# PIC32MM0032GPL036 device description
Architecture: MIPS; Family: PIC32MM1324; Series: PIC32MM
Registers are 32-bit, read-write, no defined reset value unless marked. A register's access mark holds for its fields unless they carry their own. Offsets are from the block's base; [hi:lo] are bit positions; {n}, {i} and the like mark numbered series.

## GPIO
Instances: GPIO 0x1f802300 in periph0
0x180 RPCON
  [11] IOLOCK
0x1A0 RPINR1
  [4:0] INT4R
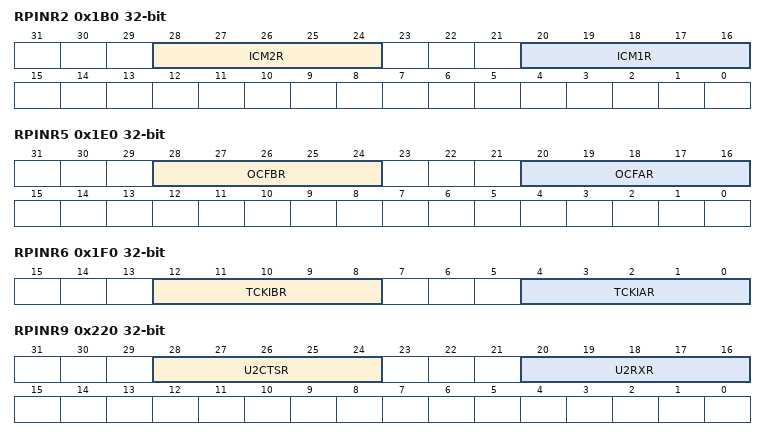
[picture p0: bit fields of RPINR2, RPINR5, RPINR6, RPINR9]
0x1B0 RPINR2
  [28:24] ICM2R, [20:16] ICM1R
0x1C0 RPINR3
  [4:0] ICM3R
0x1E0 RPINR5
  [28:24] OCFBR, [20:16] OCFAR
0x1F0 RPINR6
  [12:8] TCKIBR, [4:0] TCKIAR
0x220 RPINR9
  [28:24] U2CTSR, [20:16] U2RXR
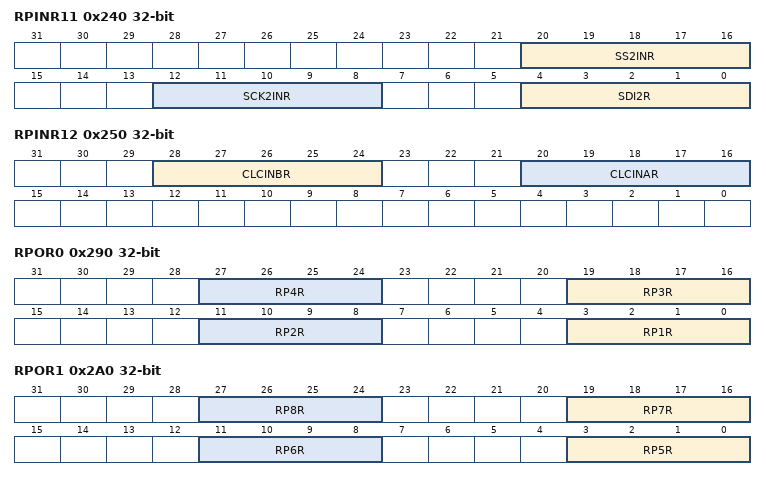
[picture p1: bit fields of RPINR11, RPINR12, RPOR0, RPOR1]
0x240 RPINR11
  [20:16] SS2INR, [12:8] SCK2INR, [4:0] SDI2R
0x250 RPINR12
  [28:24] CLCINBR, [20:16] CLCINAR
0x290 RPOR0
  [8n-5:8n-8] RP{n}R (n=1..4)
0x2A0 RPOR1
  [8n-37:8n-40] RP{n}R (n=5..8)
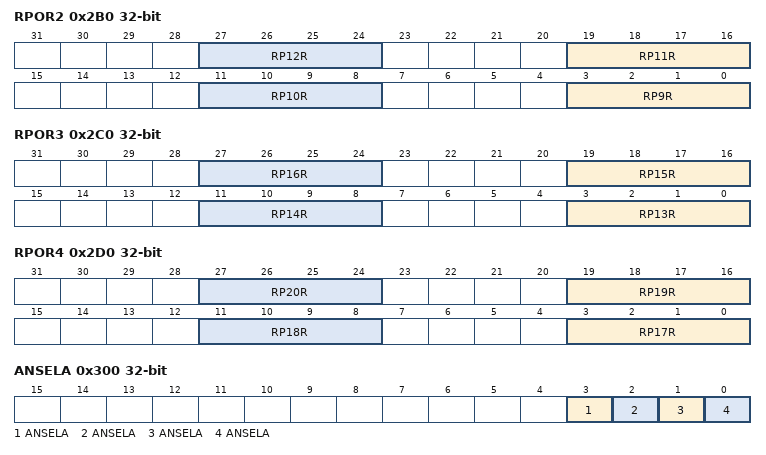
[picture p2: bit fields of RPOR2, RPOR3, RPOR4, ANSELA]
0x2B0 RPOR2
  [8n-69:8n-72] RP{n}R (n=9..12)
0x2C0 RPOR3
  [8n-101:8n-104] RP{n}R (n=13..16)
0x2D0 RPOR4
  [8n-133:8n-136] RP{n}R (n=17..20)
0x300 ANSELA
  [3] ANSELA, [2] ANSELA, [1] ANSELA, [0] ANSELA
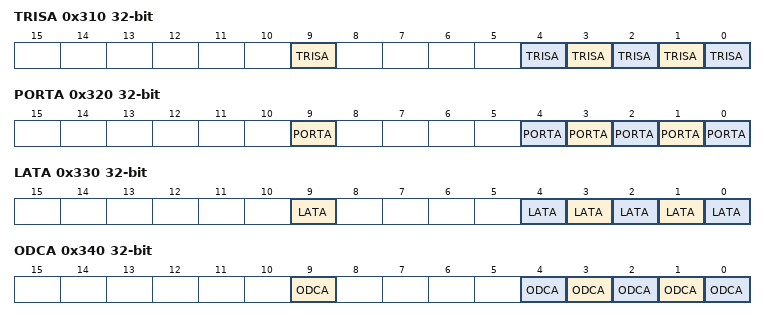
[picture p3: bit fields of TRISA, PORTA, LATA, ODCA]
0x310 TRISA
  [9] TRISA, [4] TRISA, [3] TRISA, [2] TRISA, [1] TRISA, [0] TRISA
0x320 PORTA
  [9] PORTA, [4] PORTA, [3] PORTA, [2] PORTA, [1] PORTA, [0] PORTA
0x330 LATA
  [9] LATA, [4] LATA, [3] LATA, [2] LATA, [1] LATA, [0] LATA
0x340 ODCA
  [9] ODCA, [4] ODCA, [3] ODCA, [2] ODCA, [1] ODCA, [0] ODCA
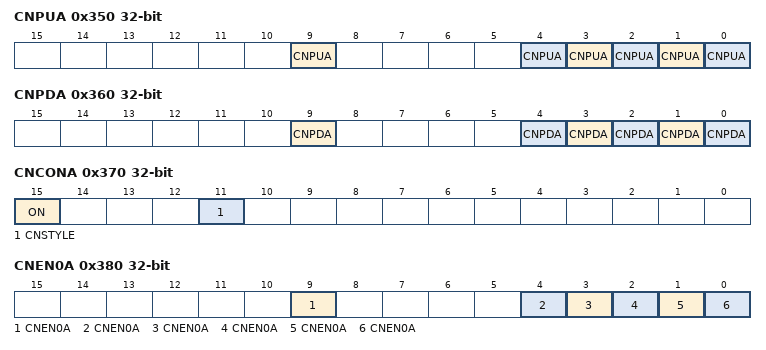
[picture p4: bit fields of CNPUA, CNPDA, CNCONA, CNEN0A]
0x350 CNPUA
  [9] CNPUA, [4] CNPUA, [3] CNPUA, [2] CNPUA, [1] CNPUA, [0] CNPUA
0x360 CNPDA
  [9] CNPDA, [4] CNPDA, [3] CNPDA, [2] CNPDA, [1] CNPDA, [0] CNPDA
0x370 CNCONA
  [15] ON, [11] CNSTYLE
0x380 CNEN0A
  [9] CNEN0A, [4] CNEN0A, [3] CNEN0A, [2] CNEN0A, [1] CNEN0A, [0] CNEN0A
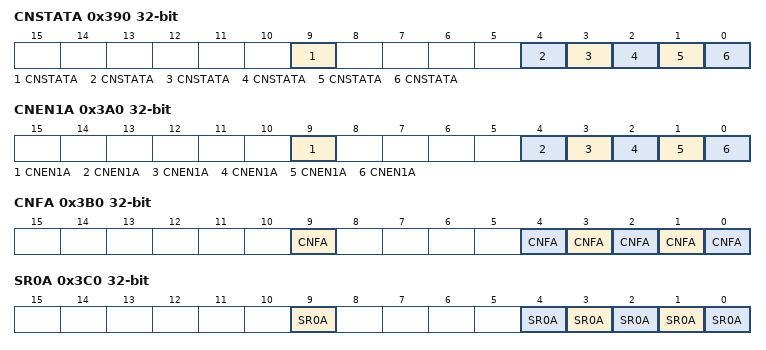
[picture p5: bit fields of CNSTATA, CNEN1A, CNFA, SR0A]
0x390 CNSTATA
  [9] CNSTATA, [4] CNSTATA, [3] CNSTATA, [2] CNSTATA, [1] CNSTATA, [0] CNSTATA
0x3A0 CNEN1A
  [9] CNEN1A, [4] CNEN1A, [3] CNEN1A, [2] CNEN1A, [1] CNEN1A, [0] CNEN1A
0x3B0 CNFA
  [9] CNFA, [4] CNFA, [3] CNFA, [2] CNFA, [1] CNFA, [0] CNFA
0x3C0 SR0A
  [9] SR0A, [4] SR0A, [3] SR0A, [2] SR0A, [1] SR0A, [0] SR0A
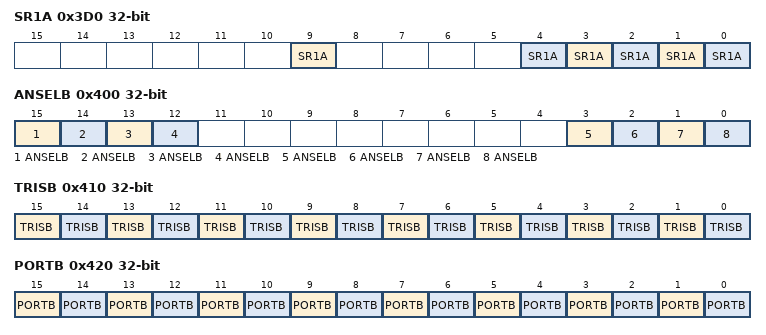
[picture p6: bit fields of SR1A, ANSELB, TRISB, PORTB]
0x3D0 SR1A
  [9] SR1A, [4] SR1A, [3] SR1A, [2] SR1A, [1] SR1A, [0] SR1A
0x400 ANSELB
  [15] ANSELB, [14] ANSELB, [13] ANSELB, [12] ANSELB, [3] ANSELB, [2] ANSELB, [1] ANSELB, [0] ANSELB
0x410 TRISB
  [15] TRISB, [14] TRISB, [13] TRISB, [12] TRISB, [11] TRISB, [10] TRISB, [9] TRISB, [8] TRISB, [7] TRISB, [6] TRISB, [5] TRISB, [4] TRISB, [3] TRISB, [2] TRISB, [1] TRISB, [0] TRISB
0x420 PORTB
  [15] PORTB, [14] PORTB, [13] PORTB, [12] PORTB, [11] PORTB, [10] PORTB, [9] PORTB, [8] PORTB, [7] PORTB, [6] PORTB, [5] PORTB, [4] PORTB, [3] PORTB, [2] PORTB, [1] PORTB, [0] PORTB
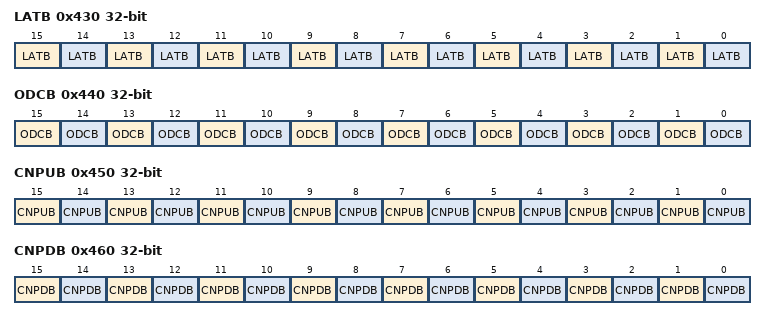
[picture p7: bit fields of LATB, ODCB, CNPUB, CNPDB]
0x430 LATB
  [15] LATB, [14] LATB, [13] LATB, [12] LATB, [11] LATB, [10] LATB, [9] LATB, [8] LATB, [7] LATB, [6] LATB, [5] LATB, [4] LATB, [3] LATB, [2] LATB, [1] LATB, [0] LATB
0x440 ODCB
  [15] ODCB, [14] ODCB, [13] ODCB, [12] ODCB, [11] ODCB, [10] ODCB, [9] ODCB, [8] ODCB, [7] ODCB, [6] ODCB, [5] ODCB, [4] ODCB, [3] ODCB, [2] ODCB, [1] ODCB, [0] ODCB
0x450 CNPUB
  [15] CNPUB, [14] CNPUB, [13] CNPUB, [12] CNPUB, [11] CNPUB, [10] CNPUB, [9] CNPUB, [8] CNPUB, [7] CNPUB, [6] CNPUB, [5] CNPUB, [4] CNPUB, [3] CNPUB, [2] CNPUB, [1] CNPUB, [0] CNPUB
0x460 CNPDB
  [15] CNPDB, [14] CNPDB, [13] CNPDB, [12] CNPDB, [11] CNPDB, [10] CNPDB, [9] CNPDB, [8] CNPDB, [7] CNPDB, [6] CNPDB, [5] CNPDB, [4] CNPDB, [3] CNPDB, [2] CNPDB, [1] CNPDB, [0] CNPDB
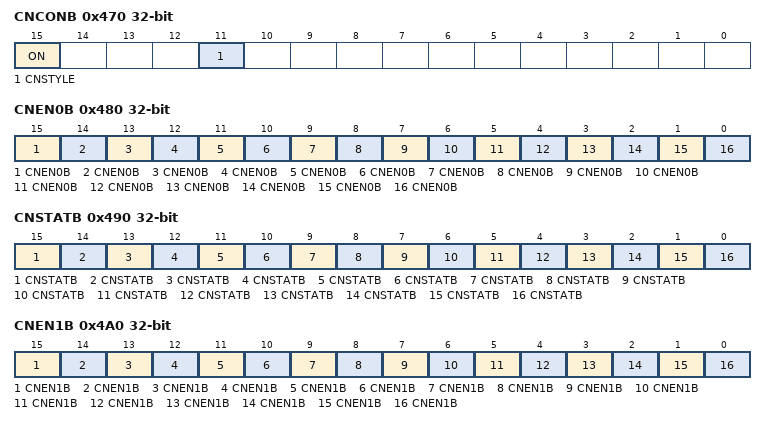
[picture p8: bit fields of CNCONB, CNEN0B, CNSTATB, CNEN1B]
0x470 CNCONB
  [15] ON, [11] CNSTYLE
0x480 CNEN0B
  [15] CNEN0B, [14] CNEN0B, [13] CNEN0B, [12] CNEN0B, [11] CNEN0B, [10] CNEN0B, [9] CNEN0B, [8] CNEN0B, [7] CNEN0B, [6] CNEN0B, [5] CNEN0B, [4] CNEN0B, [3] CNEN0B, [2] CNEN0B, [1] CNEN0B, [0] CNEN0B
0x490 CNSTATB
  [15] CNSTATB, [14] CNSTATB, [13] CNSTATB, [12] CNSTATB, [11] CNSTATB, [10] CNSTATB, [9] CNSTATB, [8] CNSTATB, [7] CNSTATB, [6] CNSTATB, [5] CNSTATB, [4] CNSTATB, [3] CNSTATB, [2] CNSTATB, [1] CNSTATB, [0] CNSTATB
0x4A0 CNEN1B
  [15] CNEN1B, [14] CNEN1B, [13] CNEN1B, [12] CNEN1B, [11] CNEN1B, [10] CNEN1B, [9] CNEN1B, [8] CNEN1B, [7] CNEN1B, [6] CNEN1B, [5] CNEN1B, [4] CNEN1B, [3] CNEN1B, [2] CNEN1B, [1] CNEN1B, [0] CNEN1B
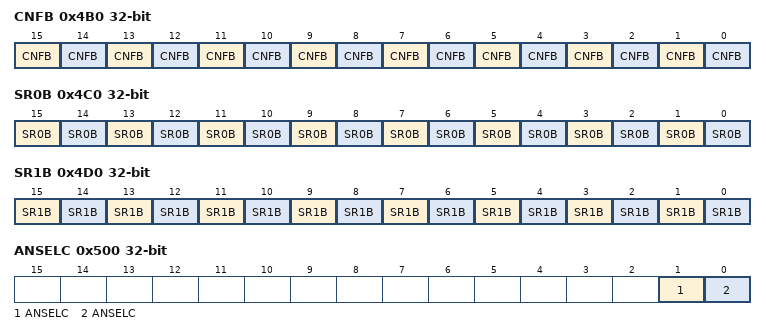
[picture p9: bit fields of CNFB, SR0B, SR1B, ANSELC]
0x4B0 CNFB
  [15] CNFB, [14] CNFB, [13] CNFB, [12] CNFB, [11] CNFB, [10] CNFB, [9] CNFB, [8] CNFB, [7] CNFB, [6] CNFB, [5] CNFB, [4] CNFB, [3] CNFB, [2] CNFB, [1] CNFB, [0] CNFB
0x4C0 SR0B
  [15] SR0B, [14] SR0B, [13] SR0B, [12] SR0B, [11] SR0B, [10] SR0B, [9] SR0B, [8] SR0B, [7] SR0B, [6] SR0B, [5] SR0B, [4] SR0B, [3] SR0B, [2] SR0B, [1] SR0B, [0] SR0B
0x4D0 SR1B
  [15] SR1B, [14] SR1B, [13] SR1B, [12] SR1B, [11] SR1B, [10] SR1B, [9] SR1B, [8] SR1B, [7] SR1B, [6] SR1B, [5] SR1B, [4] SR1B, [3] SR1B, [2] SR1B, [1] SR1B, [0] SR1B
0x500 ANSELC
  [1] ANSELC, [0] ANSELC
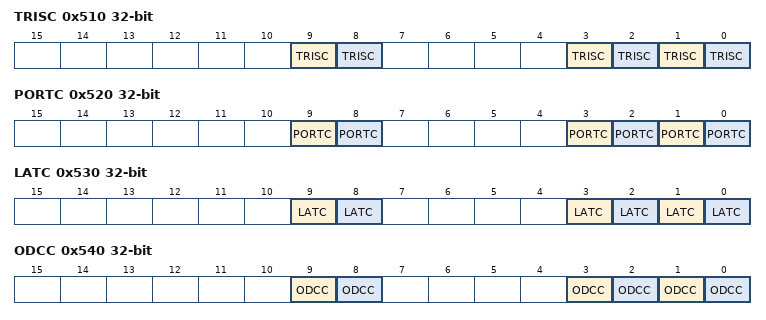
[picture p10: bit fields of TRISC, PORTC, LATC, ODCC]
0x510 TRISC
  [9] TRISC, [8] TRISC, [3] TRISC, [2] TRISC, [1] TRISC, [0] TRISC
0x520 PORTC
  [9] PORTC, [8] PORTC, [3] PORTC, [2] PORTC, [1] PORTC, [0] PORTC
0x530 LATC
  [9] LATC, [8] LATC, [3] LATC, [2] LATC, [1] LATC, [0] LATC
0x540 ODCC
  [9] ODCC, [8] ODCC, [3] ODCC, [2] ODCC, [1] ODCC, [0] ODCC
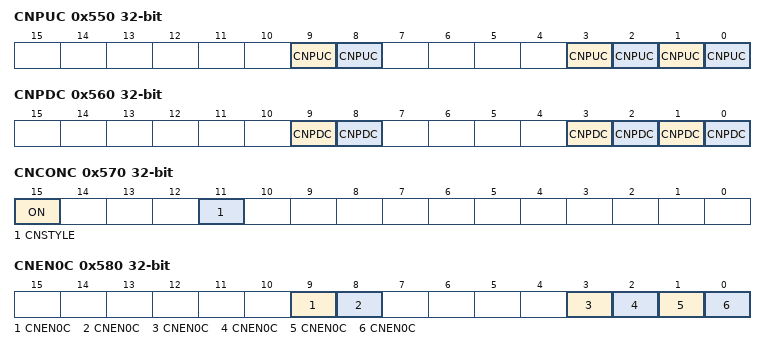
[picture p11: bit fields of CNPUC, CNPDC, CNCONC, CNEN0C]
0x550 CNPUC
  [9] CNPUC, [8] CNPUC, [3] CNPUC, [2] CNPUC, [1] CNPUC, [0] CNPUC
0x560 CNPDC
  [9] CNPDC, [8] CNPDC, [3] CNPDC, [2] CNPDC, [1] CNPDC, [0] CNPDC
0x570 CNCONC
  [15] ON, [11] CNSTYLE
0x580 CNEN0C
  [9] CNEN0C, [8] CNEN0C, [3] CNEN0C, [2] CNEN0C, [1] CNEN0C, [0] CNEN0C
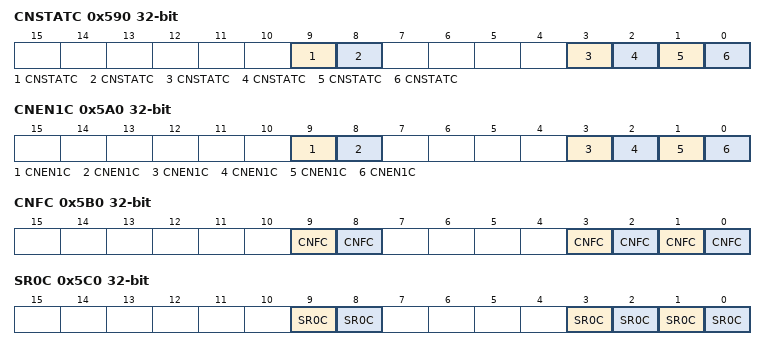
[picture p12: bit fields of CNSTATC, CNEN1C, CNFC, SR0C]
0x590 CNSTATC
  [9] CNSTATC, [8] CNSTATC, [3] CNSTATC, [2] CNSTATC, [1] CNSTATC, [0] CNSTATC
0x5A0 CNEN1C
  [9] CNEN1C, [8] CNEN1C, [3] CNEN1C, [2] CNEN1C, [1] CNEN1C, [0] CNEN1C
0x5B0 CNFC
  [9] CNFC, [8] CNFC, [3] CNFC, [2] CNFC, [1] CNFC, [0] CNFC
0x5C0 SR0C
  [9] SR0C, [8] SR0C, [3] SR0C, [2] SR0C, [1] SR0C, [0] SR0C
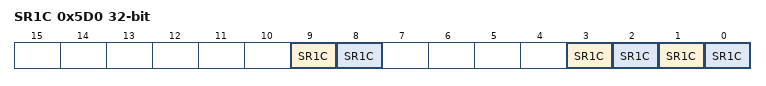
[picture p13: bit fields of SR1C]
0x5D0 SR1C
  [9] SR1C, [8] SR1C, [3] SR1C, [2] SR1C, [1] SR1C, [0] SR1C

## Notices in the file
Copyright (c) 2019 Microchip Technology Inc.
SPDX-License-Identifier: Apache-2.0
Licensed under the Apache License, Version 2.0 (the "License");
you may not use this file except in compliance with the License.
You may obtain a copy of the License at
http://www.apache.org/licenses/LICENSE-2.0
Unless required by applicable law or agreed to in writing, software
distributed under the License is distributed on an "AS IS" BASIS,
WITHOUT WARRANTIES OR CONDITIONS OF ANY KIND, either express or implied.
See the License for the specific language governing permissions and
limitations under the License.
